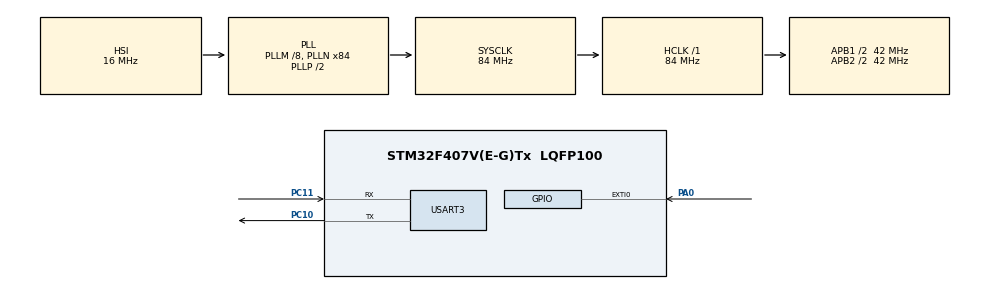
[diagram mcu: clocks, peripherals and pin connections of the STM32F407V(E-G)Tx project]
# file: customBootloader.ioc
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Mcu.Family=STM32F4
Mcu.Name=STM32F407V(E-G)Tx
Mcu.Package=LQFP100
NVIC.EXTI0_IRQn=true\:0\:0\:false\:false\:true\:true\:true
NVIC.PriorityGroup=NVIC_PRIORITYGROUP_0
NVIC.USART3_IRQn=true\:0\:0\:false\:false\:true\:true\:true
PA0-WKUP.Signal=GPXTI0
PC10.Mode=Asynchronous
PC10.Signal=USART3_TX
PC11.Mode=Asynchronous
PC11.Signal=USART3_RX
ProjectManager.HeapSize=0x200
ProjectManager.StackSize=0x400
ProjectManager.TargetToolchain=STM32CubeIDE
RCC.48MHZClocksFreq_Value=24000000
RCC.AHBFreq_Value=84000000
RCC.APB1CLKDivider=RCC_HCLK_DIV2
RCC.APB1Freq_Value=42000000
RCC.APB1TimFreq_Value=84000000
RCC.APB2CLKDivider=RCC_HCLK_DIV2
RCC.APB2Freq_Value=42000000
RCC.APB2TimFreq_Value=84000000
RCC.CortexFreq_Value=84000000
RCC.HCLKFreq_Value=84000000
RCC.HSE_VALUE=8000000
RCC.HSI_VALUE=16000000
RCC.LSE_VALUE=32768
RCC.PLLM=8
RCC.PLLN=84
RCC.PLLQ=7
RCC.SYSCLKFreq_VALUE=84000000
RCC.SYSCLKSource=RCC_SYSCLKSOURCE_PLLCLK
RCC.VCOOutputFreq_Value=168000000
USART3.VirtualMode=VM_ASYNC
VP_CRC_VS_CRC.Mode=CRC_Activate
board=STM32F407G-DISC1

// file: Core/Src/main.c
/* USER CODE BEGIN Header */
/**
  ******************************************************************************
  * @file           : main.c
  * @brief          : Main program body
  ******************************************************************************
  * @attention
  *
  * <h2><center>&copy; Copyright (c) 2023 STMicroelectronics.
  * All rights reserved.</center></h2>
  *
  * This software component is licensed by ST under BSD 3-Clause license,
  * the "License"; You may not use this file except in compliance with the
  * License. You may obtain a copy of the License at:
  *                        opensource.org/licenses/BSD-3-Clause
  *
  ******************************************************************************
  */
/* USER CODE END Header */
#include <send_message_to_host.h>
#include "main.h"

/* USER CODE BEGIN Includes */
#include  <stdbool.h>
/* USER CODE END Includes */

CRC_HandleTypeDef hcrc;

UART_HandleTypeDef huart3;

void SystemClock_Config(void);
static void MX_GPIO_Init(void);
static void MX_CRC_Init(void);
static void MX_USART3_UART_Init(void);
/* USER CODE BEGIN PFP */
#define FLASH_BASE_ADDRESS_SECTOR_0  0x08000000
#define FLASH_BASE_ADDRESS_SECTOR_1  0x08004000
#define FLASH_BASE_ADDRESS_SECTOR_2  0x08008000
#define FLASH_BASE_ADDRESS_SECTOR_3  0x0800C000
#define FLASH_BASE_ADDRESS_SECTOR_4  0x08010000
#define FLASH_BASE_ADDRESS_SECTOR_5  0x08020000
#define FLASH_BASE_ADDRESS_SECTOR_6  0x08040000
#define FLASH_BASE_ADDRESS_SECTOR_7  0x08060000
#define FLASH_BASE_ADDRESS_SECTOR_8  0x08080000
#define FLASH_BASE_ADDRESS_SECTOR_9  0x080A0000
#define FLASH_BASE_ADDRESS_SECTOR_10 0x080C0000
#define FLASH_BASE_ADDRESS_SECTOR_11 0x080E0000

/* USER CODE END PFP */

/* USER CODE BEGIN 0 */

void bootloader_jump_to_user_app(void)
{
	void ** base_add_ptr = (void **)(FLASH_BASE_ADDRESS_SECTOR_2 + 4);
	void (*app_reset_handler)(void) = (void(*)(void)) (*base_add_ptr); /*Adresi func pointer a dönüştür.*/

	//uint32_t msp_value = *(volatile uint32_t *)FLASH_SECTOR2_BASE_ADDRESS;
	//This function comes from CMSIS.
	//__set_MSP(msp_value);

	app_reset_handler();
}

/* USER CODE END 0 */

int main(void)
{

  /* MCU Configuration--------------------------------------------------------*/

  /* Reset of all peripherals, Initializes the Flash interface and the Systick. */
  HAL_Init();

  /* Configure the system clock */
  SystemClock_Config();

  /* Initialize all configured peripherals */
  MX_GPIO_Init();
  MX_CRC_Init();
  MX_USART3_UART_Init();
  /* USER CODE BEGIN 2 */

  /* Lets check whether button is pressed or not, if not pressed jump to user application */
	if (HAL_GPIO_ReadPin(GPIOA, GPIO_PIN_0) == GPIO_PIN_SET)
	{
	  //we should continue in bootloader mode
		send_message_to_host((uint8_t) TX_BL_IS_READY);
	  bootloader_uart_read_data();
	}
	else
	{
	//jump to user application
		send_message_to_host((uint8_t) TX_USER_APP_RUNNING);
    /*Add sector info*/
	  bootloader_jump_to_user_app();
	}

  /* USER CODE END 2 */

  /* Infinite loop */
  while (1)
  {

  }
}

void SystemClock_Config(void)
{
  RCC_OscInitTypeDef RCC_OscInitStruct = {0};
  RCC_ClkInitTypeDef RCC_ClkInitStruct = {0};

  /** Configure the main internal regulator output voltage
  */
  __HAL_RCC_PWR_CLK_ENABLE();
  __HAL_PWR_VOLTAGESCALING_CONFIG(PWR_REGULATOR_VOLTAGE_SCALE1);
  /** Initializes the RCC Oscillators according to the specified parameters
  * in the RCC_OscInitTypeDef structure.
  */
  RCC_OscInitStruct.OscillatorType = RCC_OSCILLATORTYPE_HSI;
  RCC_OscInitStruct.HSIState = RCC_HSI_ON;
  RCC_OscInitStruct.HSICalibrationValue = RCC_HSICALIBRATION_DEFAULT;
  RCC_OscInitStruct.PLL.PLLState = RCC_PLL_ON;
  RCC_OscInitStruct.PLL.PLLSource = RCC_PLLSOURCE_HSI;
  RCC_OscInitStruct.PLL.PLLM = 8;
  RCC_OscInitStruct.PLL.PLLN = 84;
  RCC_OscInitStruct.PLL.PLLP = RCC_PLLP_DIV2;
  RCC_OscInitStruct.PLL.PLLQ = 7;
  if (HAL_RCC_OscConfig(&RCC_OscInitStruct) != HAL_OK)
  {
    Error_Handler();
  }
  /** Initializes the CPU, AHB and APB buses clocks
  */
  RCC_ClkInitStruct.ClockType = RCC_CLOCKTYPE_HCLK|RCC_CLOCKTYPE_SYSCLK
                              |RCC_CLOCKTYPE_PCLK1|RCC_CLOCKTYPE_PCLK2;
  RCC_ClkInitStruct.SYSCLKSource = RCC_SYSCLKSOURCE_PLLCLK;
  RCC_ClkInitStruct.AHBCLKDivider = RCC_SYSCLK_DIV1;
  RCC_ClkInitStruct.APB1CLKDivider = RCC_HCLK_DIV2;
  RCC_ClkInitStruct.APB2CLKDivider = RCC_HCLK_DIV2;

  if (HAL_RCC_ClockConfig(&RCC_ClkInitStruct, FLASH_LATENCY_2) != HAL_OK)
  {
    Error_Handler();
  }
}

static void MX_CRC_Init(void)
{

  hcrc.Instance = CRC;
  if (HAL_CRC_Init(&hcrc) != HAL_OK)
  {
    Error_Handler();
  }

}

static void MX_USART3_UART_Init(void)
{

  huart3.Instance = USART3;
  huart3.Init.BaudRate = 115200;
  huart3.Init.WordLength = UART_WORDLENGTH_8B;
  huart3.Init.StopBits = UART_STOPBITS_1;
  huart3.Init.Parity = UART_PARITY_NONE;
  huart3.Init.Mode = UART_MODE_TX_RX;
  huart3.Init.HwFlowCtl = UART_HWCONTROL_NONE;
  huart3.Init.OverSampling = UART_OVERSAMPLING_16;
  if (HAL_UART_Init(&huart3) != HAL_OK)
  {
    Error_Handler();
  }

}

static void MX_GPIO_Init(void)
{
  GPIO_InitTypeDef GPIO_InitStruct = {0};

  /* GPIO Ports Clock Enable */
  __HAL_RCC_GPIOA_CLK_ENABLE();
  __HAL_RCC_GPIOC_CLK_ENABLE();

  /*Configure GPIO pin : PA0 */
  GPIO_InitStruct.Pin = GPIO_PIN_0;
  GPIO_InitStruct.Mode = GPIO_MODE_IT_RISING;
  GPIO_InitStruct.Pull = GPIO_NOPULL;
  HAL_GPIO_Init(GPIOA, &GPIO_InitStruct);

  /* EXTI interrupt init*/
  HAL_NVIC_SetPriority(EXTI0_IRQn, 0, 0);
  HAL_NVIC_EnableIRQ(EXTI0_IRQn);

}

void Error_Handler(void)
{
  __disable_irq();
  while (1)
  {
  }
}

/************************ (C) COPYRIGHT STMicroelectronics *****END OF FILE****/
